# RA6M1 register map
Vendor: Renesas Electronics Corporation; Series: RA6; File version: 1.2
CPU: CM4 r0p1, little endian, MPU, FPU, VTOR, 4 interrupt priority bits
Registers are 8-bit, read-write, reset 0x0 unless marked. A register's access mark holds for its fields unless they carry their own. Offsets are from the block's base; [hi:lo] are bit positions; lines under a group give offsets from that group; {n}, {i} and the like mark numbered series; 'fields as' and 'values as' point back to an identical list.

## PMISC — Miscellaneous Port Control Register
Base 0x40040D00
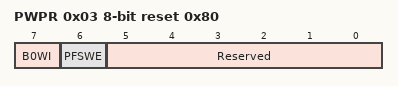
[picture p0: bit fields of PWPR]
0x03 PWPR reset 0x80 — Write-Protect Register
  [7] B0WI — PFSWE Bit Write Disable
    0=Writing to the PFSWE bit is enabled; 1=Writing to the PFSWE bit is disabled
  [6] PFSWE — PFS Register Write Enable
    0=Writing to the PFS register is disabled; 1=Writing to the PFS register is enabled
  [5:0] Reserved — These bits are read as 000000. The write value should be 000000.

## MMPU — Bus Master MPU
Base 0x40000000
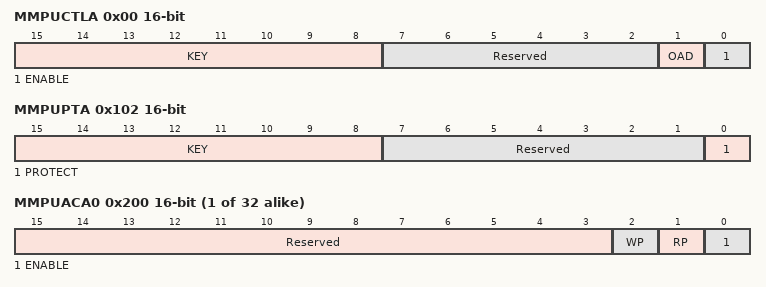
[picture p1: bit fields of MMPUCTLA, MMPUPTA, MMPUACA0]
0x00 MMPUCTLA 16-bit — Bus Master MPU Control Register
  [15:8] KEY wo — Write Keyword The data written to these bits are not stored.
    165=Writing to the OAD and ENABLE bit is valid, when the KEY bits are written 0xA5; other=others (Writing to the OAD and ENABLE bit is invalid.)
  [7:2] Reserved — These bits are read as 000000. The write value should be 000000.
  [1] OAD — Operation After Detection
    0=Non-maskable interrupt; 1=Internal reset
  [0] ENABLE — Master Group Enable
    0=Master Group A disabled. Permission of all regions.; 1=Master Group A enabled. Protection of all regions.
0x102 MMPUPTA 16-bit — Group A Protection of Register
  [15:8] KEY wo — Write Keyword The data written to these bits are not stored.
    165=Writing to the PROTECT bit is valid, when the KEY bits are written 0xA5; other=others (Writing to the PROTECT bit is invalid.)
  [7:1] Reserved — These bits are read as 0000000. The write value should be 0000000.
  [0] PROTECT — Protection of register (MMPUSAn, MMPUEAn, MMPUACAn and MMPUCTLA )
    0=All Bus Master MPU Group A register writing is possible; 1=All Bus Master MPU Group A register writing is protected. Read is possible.
{0x200+0x10*i} MMPUACA{i} (i=0..31) 16-bit — Group A Region {i} Access Control Register
  [15:3] Reserved — These bits are read as 0000000000000. The write value should be 0000000000000.
  [2] WP — Write protection
    0=Write permission; 1=Write protection
  [1] RP — Read protection
    0=Read permission; 1=Read protection
  [0] ENABLE — Region enable
    0=Group m Region n unit is disabled; 1=Group m Region n unit is enabled
{0x204+0x10*i} MMPUSA{i} (i=0..31) 32-bit (reset mask 0x3) — Group A Region {i} Start Address Register
  [31:0] MMPUSA — Region Stat Address : Address where the region starts, for use in region determination. NOTE: The low-order 2 bits are fixed to 0.
{0x208+0x10*i} MMPUEA{i} (i=0..31) 32-bit reset 0x3 (reset mask 0x3) — Group A Region {i} End Address Register
  [31:0] MMPUEA — Region End Address : Address where the region end, for use in region determination. NOTE: The low-order 2 bits are fixed to 1.

## SMPU — Bus Slave MPU
Base 0x40000C00
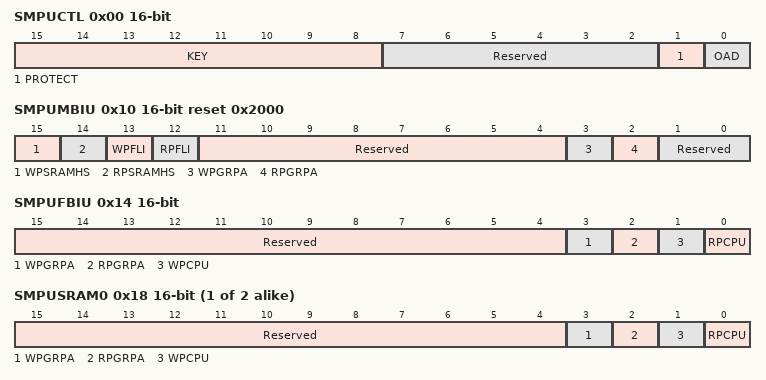
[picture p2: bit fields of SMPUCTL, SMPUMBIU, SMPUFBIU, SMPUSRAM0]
0x00 SMPUCTL 16-bit — Slave MPU Control Register
  [15:8] KEY wo — Key Code This bit is used to enable or disable writing of the PROTECT and OAD bit.
    165=Writing to the PROTECT and OAD bit is valid, when the KEY bits are written 0xA5; other=others (Writing to the PROTECT and OAD bit is invalid.)
  [7:2] Reserved — These bits are read as 000000. The write value should be 000000.
  [1] PROTECT — Protection of register
    0=All Bus Slave register writing is possible; 1=All Bus Slave register writing is protected. Read is possible.
  [0] OAD — Operation after detection
    0=Non-maskable interrupt; 1=Reset
0x10 SMPUMBIU 16-bit reset 0x2000 — Access Control Register for MBIU
  [15] WPSRAMHS — SRAMHS Write Protection
    0=Memory protection for SRAMHS writes from master group A disabled; 1=Memory protection for SRAMHS writes from master group A enabled
  [14] RPSRAMHS — SRAMHS Read Protection
    0=Memory protection for SRAMHS reads from master group A disabled; 1=Memory protection for SRAMHS reads from master group A enabled
  [13] WPFLI — Code Flash Memory Write Protection (Note: This bit is read as 1. The write value should be 1.)
    0=Setting prohibited; 1=Memory protection for code flash memory writes from master group A enabled
  [12] RPFLI — Code Flash Memory Read Protection
    0=Memory protection for code flash memory reads from master group A disabled; 1=Memory protection for code flash memory reads from master group A enabled
  [11:4] Reserved — These bits are read as 00000000. The write value should be 00000000.
  [3] WPGRPA — Master Group A Write protection
    0=Master group A write of memory protection is disabled; 1=Master group A write of memory protection is enabled
  [2] RPGRPA — Master Group A Read protection
    0=Master group A read of memory protection is disabled; 1=Master group A read of memory protection is enabled
  [1:0] Reserved — These bits are read as 00. The write value should be 00.
0x14 SMPUFBIU 16-bit — Access Control Register for FBIU
  [15:4] Reserved — These bits are read as 000000000000. The write value should be 000000000000.
  [3] WPGRPA — Master Group A Write protection
    values as SMPUMBIU.WPGRPA
  [2] RPGRPA — Master Group A Read protection
    values as SMPUMBIU.RPGRPA
  [1] WPCPU — CPU Write protection
    0=CPU write of memory protection is disabled; 1=CPU write of memory protection is enabled
  [0] RPCPU — CPU Read protection
    0=CPU read of memory protection is disabled; 1=CPU read of memory protection is enabled
{0x18+4i} SMPUSRAM{i} (i=0..1) 16-bit — Access Control Register for SRAM{i}
  fields as SMPUFBIU
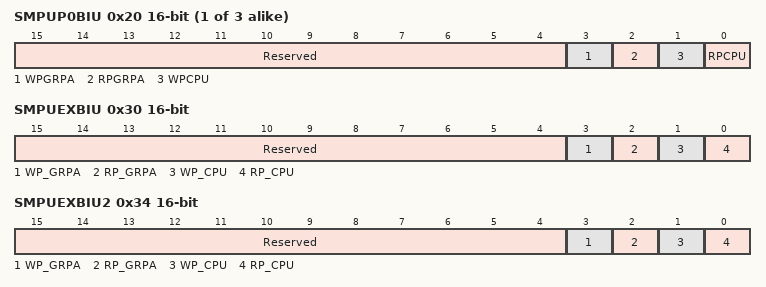
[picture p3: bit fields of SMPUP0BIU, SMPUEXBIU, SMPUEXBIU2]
0x20 SMPUP{x}BIU (x=0,2,6; step 0x4) 16-bit — Access Control Register for P{x}BIU
  fields as SMPUFBIU
0x30 SMPUEXBIU 16-bit — Access Control Register for EXBIU
  [15:4] Reserved — These bits are read as 000000000000. The write value should be 000000000000.
  [3] WP_GRPA — Master Group A Write protection
    values as SMPUMBIU.WPGRPA
  [2] RP_GRPA — Master Group A Read protection
    values as SMPUMBIU.RPGRPA
  [1] WP_CPU — CPU Write protection
    values as SMPUFBIU.WPCPU
  [0] RP_CPU — CPU Read protection
    values as SMPUFBIU.RPCPU
0x34 SMPUEXBIU2 16-bit — Access Control Register for EXBIU2
  fields as SMPUEXBIU
